VERSION ""

NS_ :

BS_:

BU_: XXX

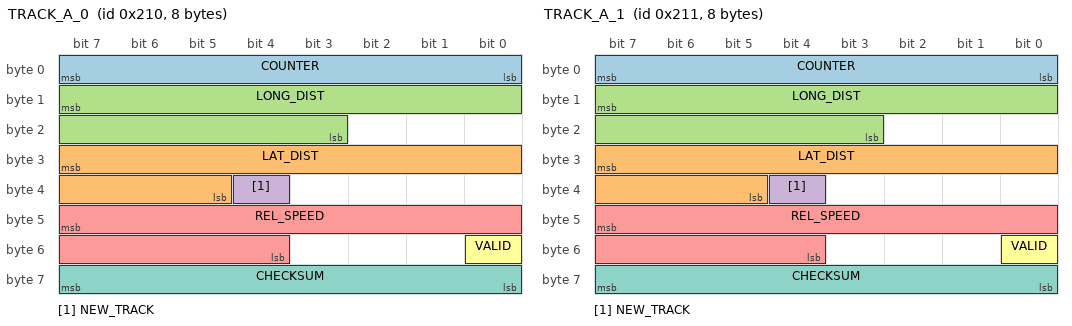
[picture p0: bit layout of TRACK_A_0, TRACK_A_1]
BO_ 528 TRACK_A_0: 8 XXX
 SG_ COUNTER : 7|8@0+ (1,0) [0|255] "" XXX
 SG_ LAT_DIST : 31|11@0- (0.04,0) [-50|50] "m" XXX
 SG_ LONG_DIST : 15|13@0+ (0.04,0) [0|300] "m" XXX
 SG_ NEW_TRACK : 36|1@0+ (1,0) [0|1] "" XXX
 SG_ REL_SPEED : 47|12@0- (0.025,0) [-100|100] "m/s" XXX
 SG_ VALID : 48|1@0+ (1,0) [0|1] "" XXX
 SG_ CHECKSUM : 63|8@0+ (1,0) [0|255] "" XXX

BO_ 529 TRACK_A_1: 8 XXX
 SG_ COUNTER : 7|8@0+ (1,0) [0|255] "" XXX
 SG_ LAT_DIST : 31|11@0- (0.04,0) [-50|50] "m" XXX
 SG_ LONG_DIST : 15|13@0+ (0.04,0) [0|300] "m" XXX
 SG_ NEW_TRACK : 36|1@0+ (1,0) [0|1] "" XXX
 SG_ REL_SPEED : 47|12@0- (0.025,0) [-100|100] "m/s" XXX
 SG_ VALID : 48|1@0+ (1,0) [0|1] "" XXX
 SG_ CHECKSUM : 63|8@0+ (1,0) [0|255] "" XXX

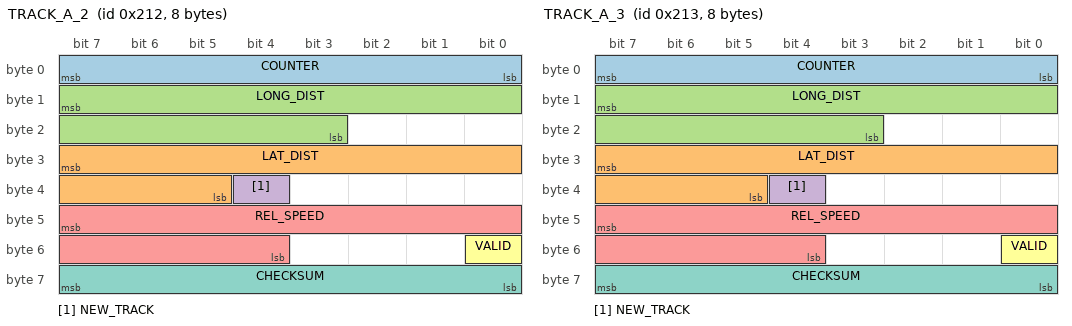
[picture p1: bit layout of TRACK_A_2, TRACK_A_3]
BO_ 530 TRACK_A_2: 8 XXX
 SG_ COUNTER : 7|8@0+ (1,0) [0|255] "" XXX
 SG_ LAT_DIST : 31|11@0- (0.04,0) [-50|50] "m" XXX
 SG_ LONG_DIST : 15|13@0+ (0.04,0) [0|300] "m" XXX
 SG_ NEW_TRACK : 36|1@0+ (1,0) [0|1] "" XXX
 SG_ REL_SPEED : 47|12@0- (0.025,0) [-100|100] "m/s" XXX
 SG_ VALID : 48|1@0+ (1,0) [0|1] "" XXX
 SG_ CHECKSUM : 63|8@0+ (1,0) [0|255] "" XXX

BO_ 531 TRACK_A_3: 8 XXX
 SG_ COUNTER : 7|8@0+ (1,0) [0|255] "" XXX
 SG_ LAT_DIST : 31|11@0- (0.04,0) [-50|50] "m" XXX
 SG_ LONG_DIST : 15|13@0+ (0.04,0) [0|300] "m" XXX
 SG_ NEW_TRACK : 36|1@0+ (1,0) [0|1] "" XXX
 SG_ REL_SPEED : 47|12@0- (0.025,0) [-100|100] "m/s" XXX
 SG_ VALID : 48|1@0+ (1,0) [0|1] "" XXX
 SG_ CHECKSUM : 63|8@0+ (1,0) [0|255] "" XXX

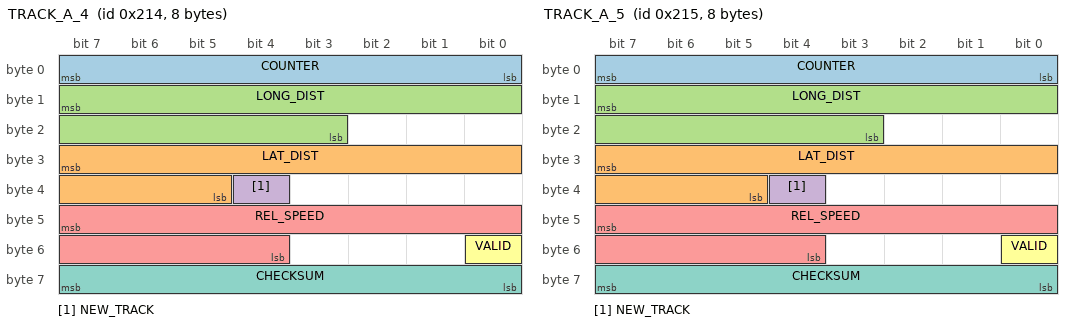
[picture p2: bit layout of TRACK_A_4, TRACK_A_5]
BO_ 532 TRACK_A_4: 8 XXX
 SG_ COUNTER : 7|8@0+ (1,0) [0|255] "" XXX
 SG_ LAT_DIST : 31|11@0- (0.04,0) [-50|50] "m" XXX
 SG_ LONG_DIST : 15|13@0+ (0.04,0) [0|300] "m" XXX
 SG_ NEW_TRACK : 36|1@0+ (1,0) [0|1] "" XXX
 SG_ REL_SPEED : 47|12@0- (0.025,0) [-100|100] "m/s" XXX
 SG_ VALID : 48|1@0+ (1,0) [0|1] "" XXX
 SG_ CHECKSUM : 63|8@0+ (1,0) [0|255] "" XXX

BO_ 533 TRACK_A_5: 8 XXX
 SG_ COUNTER : 7|8@0+ (1,0) [0|255] "" XXX
 SG_ LAT_DIST : 31|11@0- (0.04,0) [-50|50] "m" XXX
 SG_ LONG_DIST : 15|13@0+ (0.04,0) [0|300] "m" XXX
 SG_ NEW_TRACK : 36|1@0+ (1,0) [0|1] "" XXX
 SG_ REL_SPEED : 47|12@0- (0.025,0) [-100|100] "m/s" XXX
 SG_ VALID : 48|1@0+ (1,0) [0|1] "" XXX
 SG_ CHECKSUM : 63|8@0+ (1,0) [0|255] "" XXX

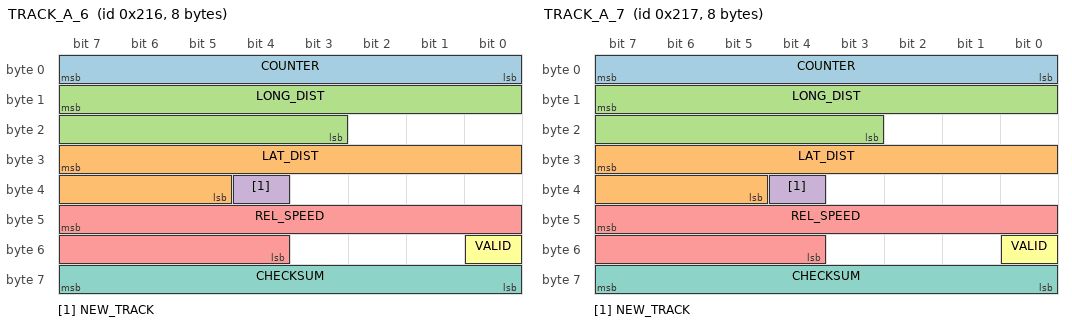
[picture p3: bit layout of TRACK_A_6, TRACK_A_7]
BO_ 534 TRACK_A_6: 8 XXX
 SG_ COUNTER : 7|8@0+ (1,0) [0|255] "" XXX
 SG_ LAT_DIST : 31|11@0- (0.04,0) [-50|50] "m" XXX
 SG_ LONG_DIST : 15|13@0+ (0.04,0) [0|300] "m" XXX
 SG_ NEW_TRACK : 36|1@0+ (1,0) [0|1] "" XXX
 SG_ REL_SPEED : 47|12@0- (0.025,0) [-100|100] "m/s" XXX
 SG_ VALID : 48|1@0+ (1,0) [0|1] "" XXX
 SG_ CHECKSUM : 63|8@0+ (1,0) [0|255] "" XXX

BO_ 535 TRACK_A_7: 8 XXX
 SG_ COUNTER : 7|8@0+ (1,0) [0|255] "" XXX
 SG_ LAT_DIST : 31|11@0- (0.04,0) [-50|50] "m" XXX
 SG_ LONG_DIST : 15|13@0+ (0.04,0) [0|300] "m" XXX
 SG_ NEW_TRACK : 36|1@0+ (1,0) [0|1] "" XXX
 SG_ REL_SPEED : 47|12@0- (0.025,0) [-100|100] "m/s" XXX
 SG_ VALID : 48|1@0+ (1,0) [0|1] "" XXX
 SG_ CHECKSUM : 63|8@0+ (1,0) [0|255] "" XXX

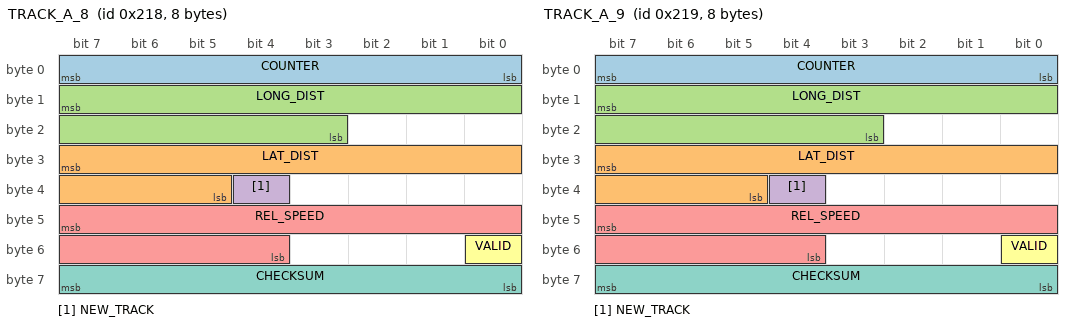
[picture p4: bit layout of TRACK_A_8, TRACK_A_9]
BO_ 536 TRACK_A_8: 8 XXX
 SG_ COUNTER : 7|8@0+ (1,0) [0|255] "" XXX
 SG_ LAT_DIST : 31|11@0- (0.04,0) [-50|50] "m" XXX
 SG_ LONG_DIST : 15|13@0+ (0.04,0) [0|300] "m" XXX
 SG_ NEW_TRACK : 36|1@0+ (1,0) [0|1] "" XXX
 SG_ REL_SPEED : 47|12@0- (0.025,0) [-100|100] "m/s" XXX
 SG_ VALID : 48|1@0+ (1,0) [0|1] "" XXX
 SG_ CHECKSUM : 63|8@0+ (1,0) [0|255] "" XXX

BO_ 537 TRACK_A_9: 8 XXX
 SG_ COUNTER : 7|8@0+ (1,0) [0|255] "" XXX
 SG_ LAT_DIST : 31|11@0- (0.04,0) [-50|50] "m" XXX
 SG_ LONG_DIST : 15|13@0+ (0.04,0) [0|300] "m" XXX
 SG_ NEW_TRACK : 36|1@0+ (1,0) [0|1] "" XXX
 SG_ REL_SPEED : 47|12@0- (0.025,0) [-100|100] "m/s" XXX
 SG_ VALID : 48|1@0+ (1,0) [0|1] "" XXX
 SG_ CHECKSUM : 63|8@0+ (1,0) [0|255] "" XXX

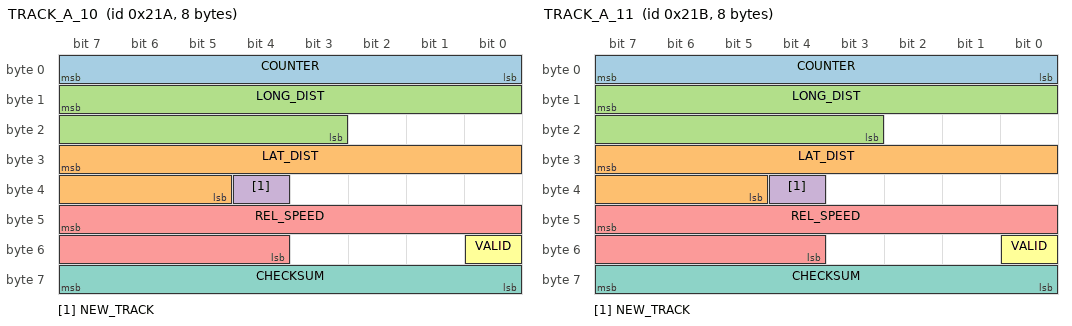
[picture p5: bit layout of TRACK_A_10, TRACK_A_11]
BO_ 538 TRACK_A_10: 8 XXX
 SG_ COUNTER : 7|8@0+ (1,0) [0|255] "" XXX
 SG_ LAT_DIST : 31|11@0- (0.04,0) [-50|50] "m" XXX
 SG_ LONG_DIST : 15|13@0+ (0.04,0) [0|300] "m" XXX
 SG_ NEW_TRACK : 36|1@0+ (1,0) [0|1] "" XXX
 SG_ REL_SPEED : 47|12@0- (0.025,0) [-100|100] "m/s" XXX
 SG_ VALID : 48|1@0+ (1,0) [0|1] "" XXX
 SG_ CHECKSUM : 63|8@0+ (1,0) [0|255] "" XXX

BO_ 539 TRACK_A_11: 8 XXX
 SG_ COUNTER : 7|8@0+ (1,0) [0|255] "" XXX
 SG_ LAT_DIST : 31|11@0- (0.04,0) [-50|50] "m" XXX
 SG_ LONG_DIST : 15|13@0+ (0.04,0) [0|300] "m" XXX
 SG_ NEW_TRACK : 36|1@0+ (1,0) [0|1] "" XXX
 SG_ REL_SPEED : 47|12@0- (0.025,0) [-100|100] "m/s" XXX
 SG_ VALID : 48|1@0+ (1,0) [0|1] "" XXX
 SG_ CHECKSUM : 63|8@0+ (1,0) [0|255] "" XXX

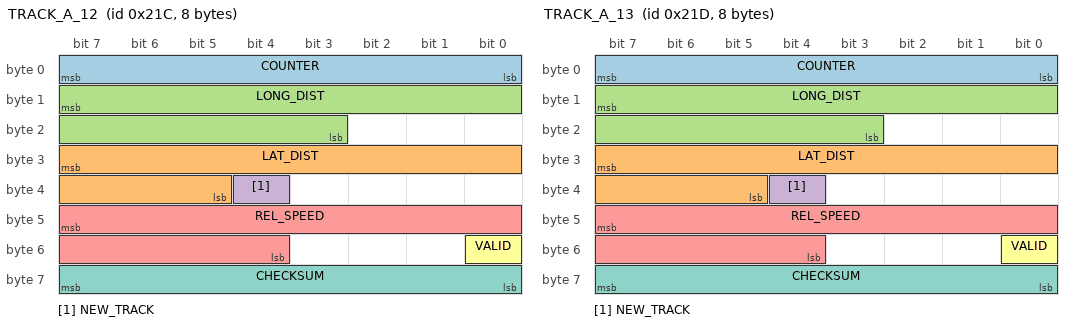
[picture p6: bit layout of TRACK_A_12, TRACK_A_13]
BO_ 540 TRACK_A_12: 8 XXX
 SG_ COUNTER : 7|8@0+ (1,0) [0|255] "" XXX
 SG_ LAT_DIST : 31|11@0- (0.04,0) [-50|50] "m" XXX
 SG_ LONG_DIST : 15|13@0+ (0.04,0) [0|300] "m" XXX
 SG_ NEW_TRACK : 36|1@0+ (1,0) [0|1] "" XXX
 SG_ REL_SPEED : 47|12@0- (0.025,0) [-100|100] "m/s" XXX
 SG_ VALID : 48|1@0+ (1,0) [0|1] "" XXX
 SG_ CHECKSUM : 63|8@0+ (1,0) [0|255] "" XXX

BO_ 541 TRACK_A_13: 8 XXX
 SG_ COUNTER : 7|8@0+ (1,0) [0|255] "" XXX
 SG_ LAT_DIST : 31|11@0- (0.04,0) [-50|50] "m" XXX
 SG_ LONG_DIST : 15|13@0+ (0.04,0) [0|300] "m" XXX
 SG_ NEW_TRACK : 36|1@0+ (1,0) [0|1] "" XXX
 SG_ REL_SPEED : 47|12@0- (0.025,0) [-100|100] "m/s" XXX
 SG_ VALID : 48|1@0+ (1,0) [0|1] "" XXX
 SG_ CHECKSUM : 63|8@0+ (1,0) [0|255] "" XXX

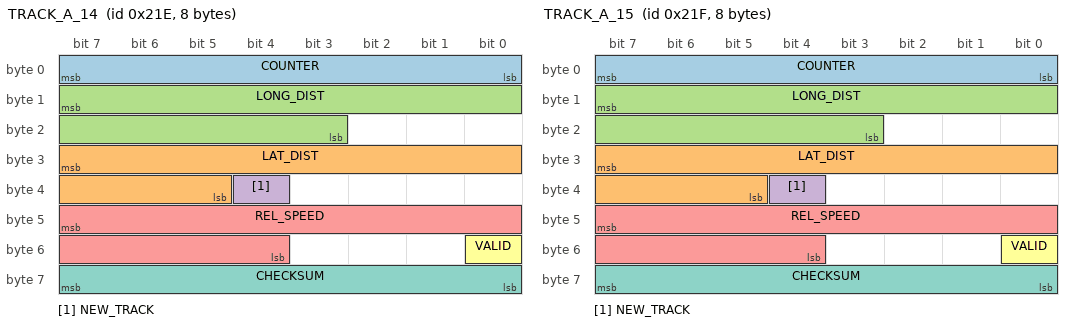
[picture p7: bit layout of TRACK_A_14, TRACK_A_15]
BO_ 542 TRACK_A_14: 8 XXX
 SG_ COUNTER : 7|8@0+ (1,0) [0|255] "" XXX
 SG_ LAT_DIST : 31|11@0- (0.04,0) [-50|50] "m" XXX
 SG_ LONG_DIST : 15|13@0+ (0.04,0) [0|300] "m" XXX
 SG_ NEW_TRACK : 36|1@0+ (1,0) [0|1] "" XXX
 SG_ REL_SPEED : 47|12@0- (0.025,0) [-100|100] "m/s" XXX
 SG_ VALID : 48|1@0+ (1,0) [0|1] "" XXX
 SG_ CHECKSUM : 63|8@0+ (1,0) [0|255] "" XXX

BO_ 543 TRACK_A_15: 8 XXX
 SG_ COUNTER : 7|8@0+ (1,0) [0|255] "" XXX
 SG_ LAT_DIST : 31|11@0- (0.04,0) [-50|50] "m" XXX
 SG_ LONG_DIST : 15|13@0+ (0.04,0) [0|300] "m" XXX
 SG_ NEW_TRACK : 36|1@0+ (1,0) [0|1] "" XXX
 SG_ REL_SPEED : 47|12@0- (0.025,0) [-100|100] "m/s" XXX
 SG_ VALID : 48|1@0+ (1,0) [0|1] "" XXX
 SG_ CHECKSUM : 63|8@0+ (1,0) [0|255] "" XXX

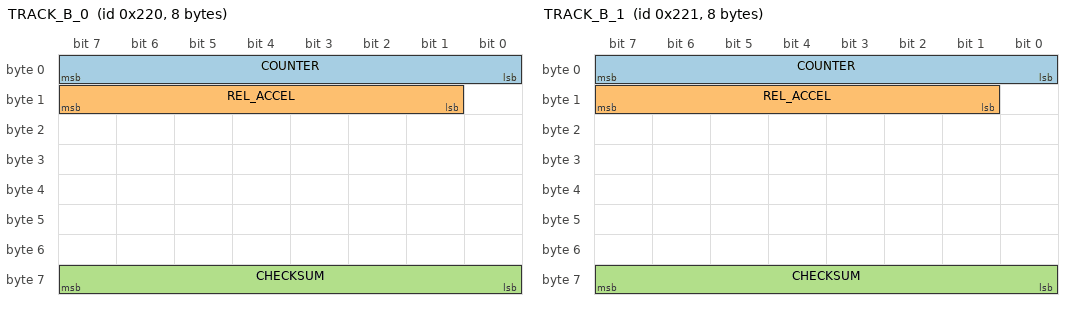
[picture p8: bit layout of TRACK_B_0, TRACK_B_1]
BO_ 544 TRACK_B_0: 8 XXX
 SG_ COUNTER : 7|8@0+ (1,0) [0|255] "" XXX
 SG_ REL_ACCEL : 15|7@0- (1,0) [-64|63] "" XXX
 SG_ CHECKSUM : 63|8@0+ (1,0) [0|255] "" XXX

BO_ 545 TRACK_B_1: 8 XXX
 SG_ COUNTER : 7|8@0+ (1,0) [0|255] "" XXX
 SG_ REL_ACCEL : 15|7@0- (1,0) [-64|63] "" XXX
 SG_ CHECKSUM : 63|8@0+ (1,0) [0|255] "" XXX

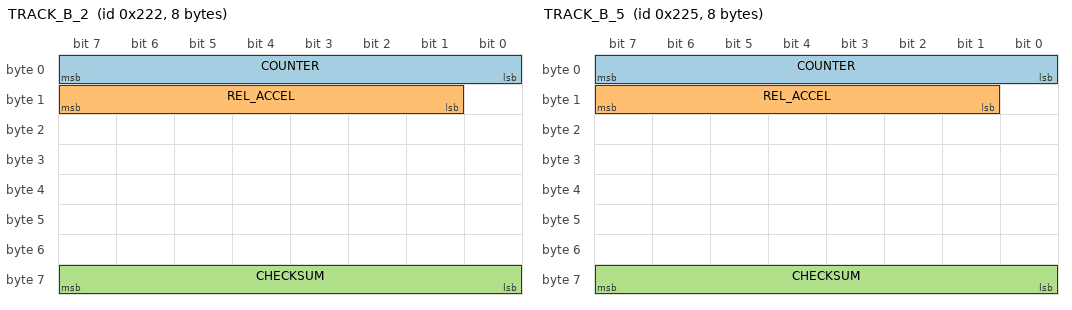
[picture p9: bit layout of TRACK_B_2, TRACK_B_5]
BO_ 546 TRACK_B_2: 8 XXX
 SG_ COUNTER : 7|8@0+ (1,0) [0|255] "" XXX
 SG_ REL_ACCEL : 15|7@0- (1,0) [-64|63] "" XXX
 SG_ CHECKSUM : 63|8@0+ (1,0) [0|255] "" XXX

BO_ 547 undefined: 8 XXX

BO_ 548 BRAKING_PEDAL: 8 XXX
 SG_ IS_BRAKING : 5|1@0+ (1,0) [0|3] "" XXX

BO_ 549 TRACK_B_5: 8 XXX
 SG_ COUNTER : 7|8@0+ (1,0) [0|255] "" XXX
 SG_ REL_ACCEL : 15|7@0- (1,0) [-64|63] "" XXX
 SG_ CHECKSUM : 63|8@0+ (1,0) [0|255] "" XXX

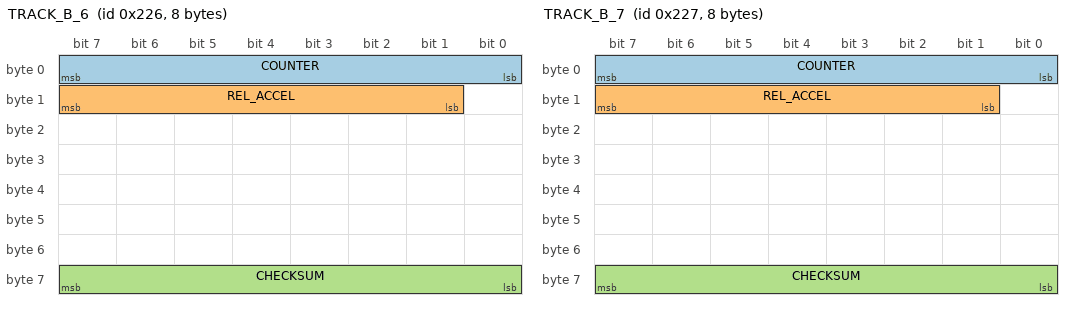
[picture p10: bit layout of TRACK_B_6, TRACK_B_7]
BO_ 550 TRACK_B_6: 8 XXX
 SG_ COUNTER : 7|8@0+ (1,0) [0|255] "" XXX
 SG_ REL_ACCEL : 15|7@0- (1,0) [-64|63] "" XXX
 SG_ CHECKSUM : 63|8@0+ (1,0) [0|255] "" XXX

BO_ 551 TRACK_B_7: 8 XXX
 SG_ COUNTER : 7|8@0+ (1,0) [0|255] "" XXX
 SG_ REL_ACCEL : 15|7@0- (1,0) [-64|63] "" XXX
 SG_ CHECKSUM : 63|8@0+ (1,0) [0|255] "" XXX

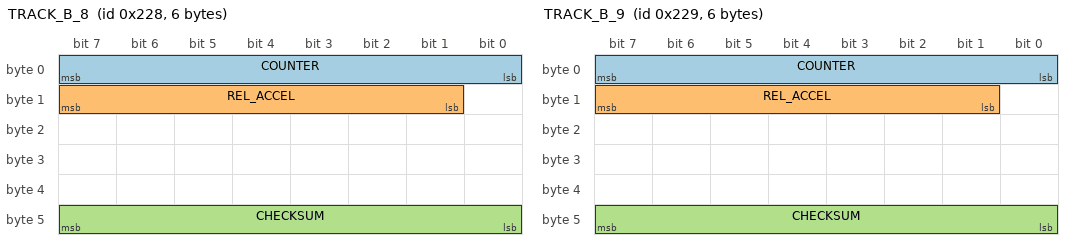
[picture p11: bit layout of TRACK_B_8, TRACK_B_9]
BO_ 552 TRACK_B_8: 6 XXX
 SG_ COUNTER : 7|8@0+ (1,0) [0|255] "" XXX
 SG_ REL_ACCEL : 15|7@0- (1,0) [-64|63] "" XXX
 SG_ CHECKSUM : 47|8@0+ (1,0) [0|255] "" XXX

BO_ 553 TRACK_B_9: 6 XXX
 SG_ COUNTER : 7|8@0+ (1,0) [0|255] "" XXX
 SG_ REL_ACCEL : 15|7@0- (1,0) [-64|63] "" XXX
 SG_ CHECKSUM : 47|8@0+ (1,0) [0|255] "" XXX

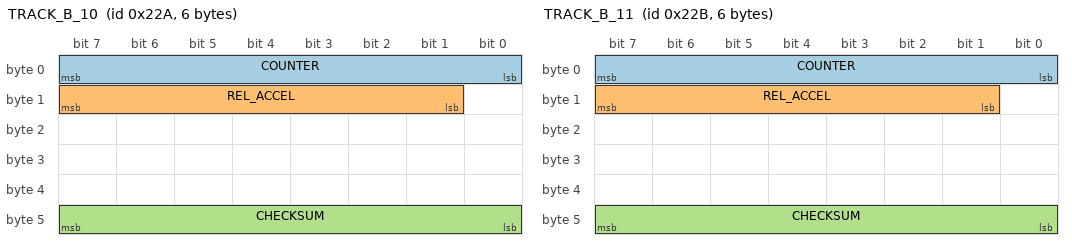
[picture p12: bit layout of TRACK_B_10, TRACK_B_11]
BO_ 554 TRACK_B_10: 6 XXX
 SG_ COUNTER : 7|8@0+ (1,0) [0|255] "" XXX
 SG_ REL_ACCEL : 15|7@0- (1,0) [-64|63] "" XXX
 SG_ CHECKSUM : 47|8@0+ (1,0) [0|255] "" XXX

BO_ 555 TRACK_B_11: 6 XXX
 SG_ COUNTER : 7|8@0+ (1,0) [0|255] "" XXX
 SG_ REL_ACCEL : 15|7@0- (1,0) [-64|63] "" XXX
 SG_ CHECKSUM : 47|8@0+ (1,0) [0|255] "" XXX

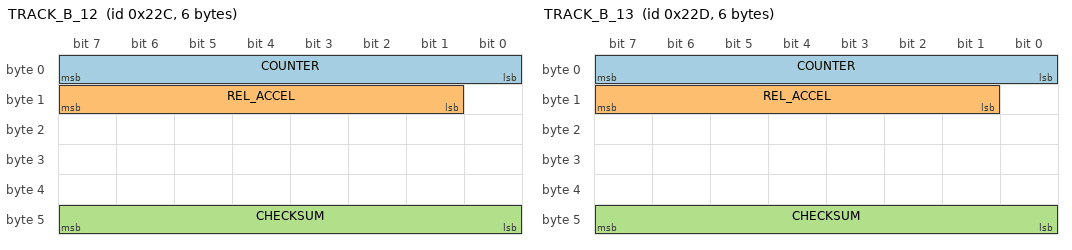
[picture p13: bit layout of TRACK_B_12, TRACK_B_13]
BO_ 556 TRACK_B_12: 6 XXX
 SG_ COUNTER : 7|8@0+ (1,0) [0|255] "" XXX
 SG_ REL_ACCEL : 15|7@0- (1,0) [-64|63] "" XXX
 SG_ CHECKSUM : 47|8@0+ (1,0) [0|255] "" XXX

BO_ 557 TRACK_B_13: 6 XXX
 SG_ COUNTER : 7|8@0+ (1,0) [0|255] "" XXX
 SG_ REL_ACCEL : 15|7@0- (1,0) [-64|63] "" XXX
 SG_ CHECKSUM : 47|8@0+ (1,0) [0|255] "" XXX

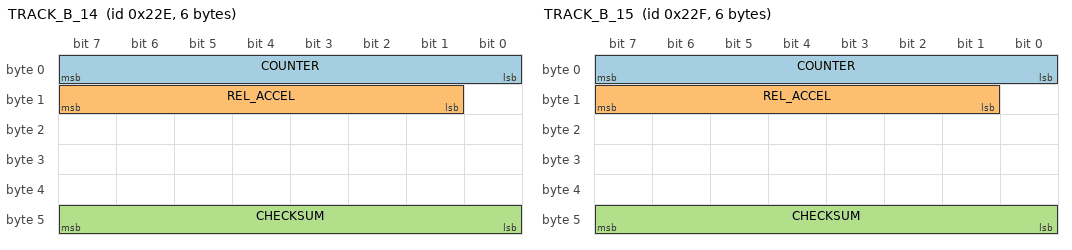
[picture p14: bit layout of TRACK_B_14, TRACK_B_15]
BO_ 558 TRACK_B_14: 6 XXX
 SG_ COUNTER : 7|8@0+ (1,0) [0|255] "" XXX
 SG_ REL_ACCEL : 15|7@0- (1,0) [-64|63] "" XXX
 SG_ CHECKSUM : 47|8@0+ (1,0) [0|255] "" XXX

BO_ 559 TRACK_B_15: 6 XXX
 SG_ COUNTER : 7|8@0+ (1,0) [0|255] "" XXX
 SG_ REL_ACCEL : 15|7@0- (1,0) [-64|63] "" XXX
 SG_ CHECKSUM : 47|8@0+ (1,0) [0|255] "" XXX

BO_ 1552 CONTAINS_LRES_SPEED: 8 XXX
 SG_ SPEED_LOWRES : 16|8@1+ (1,0) [0|255] "km/h?" XXX
 SG_ NEW_SIGNAL_1 : 7|8@0+ (1,0) [0|255] "" XXX

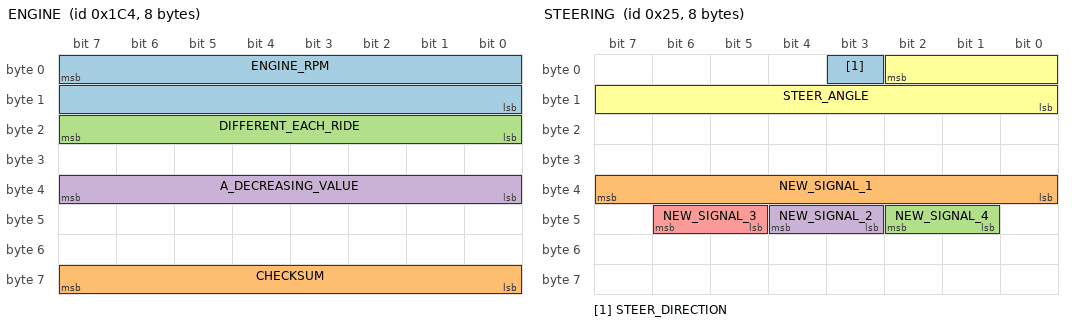
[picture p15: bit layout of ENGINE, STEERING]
BO_ 452 ENGINE: 8 XXX
 SG_ ENGINE_RPM : 7|16@0+ (1,0) [0|65535] "rpm" XXX
 SG_ CHECKSUM : 63|8@0+ (1,0) [0|255] "" XXX
 SG_ DIFFERENT_EACH_RIDE : 23|8@0+ (1,0) [0|255] "" XXX
 SG_ A_DECREASING_VALUE : 39|8@0+ (1,0) [0|255] "" XXX

BO_ 37 STEERING: 8 XXX
 SG_ STEER_DIRECTION : 3|1@0+ (1,0) [0|1] "" XXX
 SG_ NEW_SIGNAL_1 : 39|8@0+ (1,0) [0|255] "" XXX
 SG_ NEW_SIGNAL_4 : 42|2@0- (1,0) [0|3] "" XXX
 SG_ NEW_SIGNAL_2 : 44|2@0- (1,0) [0|255] "" XXX
 SG_ NEW_SIGNAL_3 : 46|2@0- (1,0) [0|3] "" XXX
 SG_ STEER_ANGLE : 2|11@0- (1,0) [-350|350] "" XXX

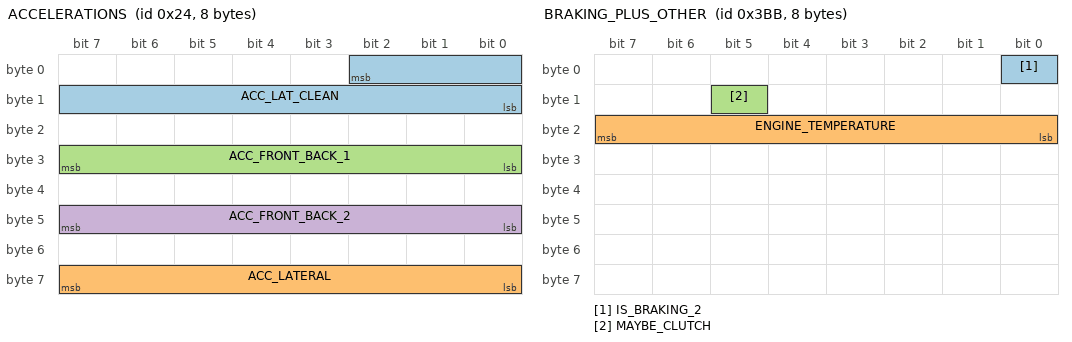
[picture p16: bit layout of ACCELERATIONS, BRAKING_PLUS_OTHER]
BO_ 36 ACCELERATIONS: 8 XXX
 SG_ ACC_LAT_CLEAN : 2|11@0- (1,0) [0|255] "" XXX
 SG_ ACC_LATERAL : 63|8@0- (1,0) [0|255] "" XXX
 SG_ ACC_FRONT_BACK_1 : 31|8@0- (1,0) [0|255] "" XXX
 SG_ ACC_FRONT_BACK_2 : 47|8@0- (1,0) [0|255] "" XXX

BO_ 947 LOW_RES_INDICATORS: 8 XXX
 SG_ LOW_RES_ACC_PEDAL : 23|7@0+ (1,0) [0|63] "" XXX
 SG_ LOW_RES_RPM : 7|16@0+ (1,0) [0|255] "rpm" XXX

BO_ 955 BRAKING_PLUS_OTHER: 8 XXX
 SG_ IS_BRAKING_2 : 0|1@0+ (1,0) [0|1] "" XXX
 SG_ ENGINE_TEMPERATURE : 23|8@0+ (1,0) [0|255] "" XXX
 SG_ MAYBE_CLUTCH : 13|1@0+ (1,0) [0|1] "" XXX

BO_ 1595 CONTAINS_TIME: 8 XXX
 SG_ TIME_ON : 55|16@0+ (0.1,0) [0|65535] "s" XXX
 SG_ BETWEEN_RIDES : 7|32@0+ (1,0) [0|4294967295] "" XXX

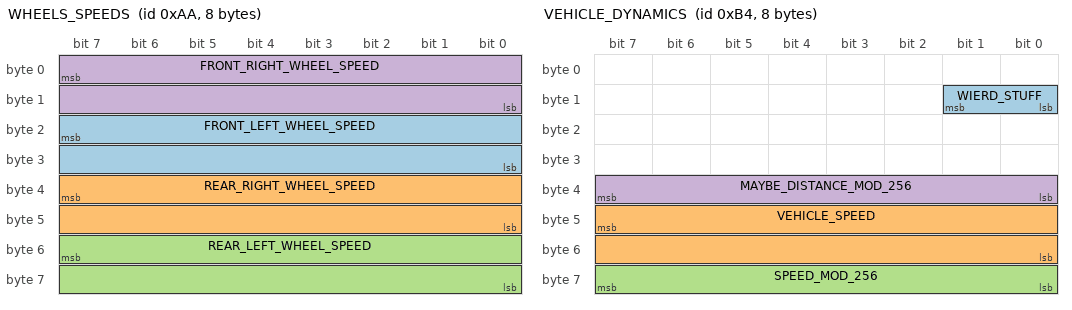
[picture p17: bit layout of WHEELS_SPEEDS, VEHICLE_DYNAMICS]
BO_ 170 WHEELS_SPEEDS: 8 XXX
 SG_ FRONT_LEFT_WHEEL_SPEED : 23|16@0+ (0.01,-67.67) [0|65535] "km/h" XXX
 SG_ REAR_RIGHT_WHEEL_SPEED : 39|16@0+ (0.01,-67.67) [0|65535] "km/h" XXX
 SG_ REAR_LEFT_WHEEL_SPEED : 55|16@0+ (0.01,-67.67) [0|65535] "km/h" XXX
 SG_ FRONT_RIGHT_WHEEL_SPEED : 7|16@0+ (0.01,-67.67) [0|65535] "km/h" XXX

BO_ 180 VEHICLE_DYNAMICS: 8 XXX
 SG_ WIERD_STUFF : 8|2@1+ (1,0) [0|3] "" XXX
 SG_ VEHICLE_SPEED : 47|16@0+ (0.01,0) [0|255] "km/h" XXX
 SG_ SPEED_MOD_256 : 63|8@0- (1,0) [0|255] "" XXX
 SG_ MAYBE_DISTANCE_MOD_256 : 39|8@0+ (1,0) [0|255] "" XXX

BO_ 186 NEW_MSG_9: 8 XXX
 SG_ NEW_SIGNAL_2 : 31|8@0+ (1,0) [0|255] "" XXX

BO_ 565 NEW_MSG_10: 8 XXX

BO_ 464 NEW_MSG_11: 8 XXX

BO_ 426 NEW_MSG_5: 8 XXX
 SG_ CONSTANT : 47|8@0+ (1,0) [0|255] "" XXX

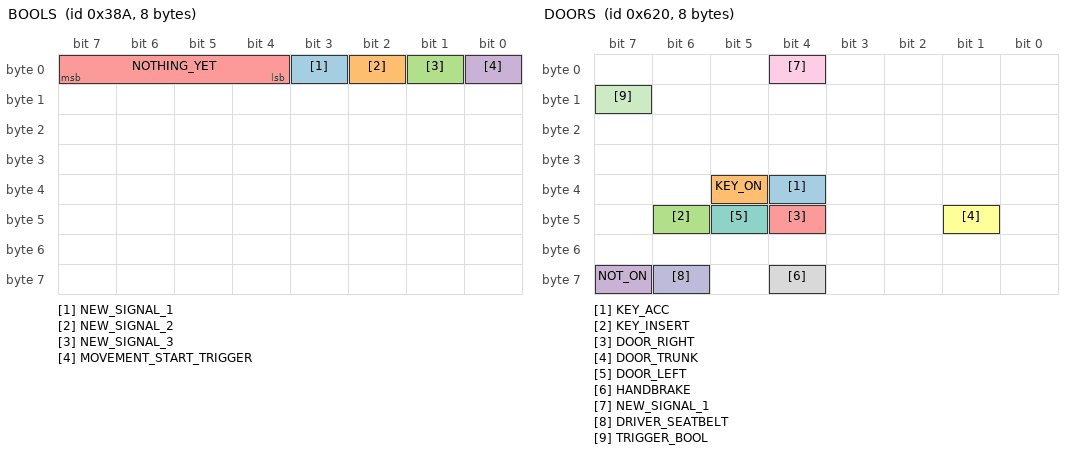
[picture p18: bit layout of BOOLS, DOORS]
BO_ 906 BOOLS: 8 XXX
 SG_ NEW_SIGNAL_1 : 3|1@0+ (1,0) [0|1] "" XXX
 SG_ NEW_SIGNAL_2 : 2|1@0+ (1,0) [0|1] "" XXX
 SG_ NEW_SIGNAL_3 : 1|1@0+ (1,0) [0|1] "" XXX
 SG_ MOVEMENT_START_TRIGGER : 0|1@0+ (1,0) [0|1] "" XXX
 SG_ NOTHING_YET : 7|4@0+ (1,0) [0|127] "" XXX

BO_ 979 LOW_RES_ACCELERATOR: 8 XXX
 SG_ VERY_LRES_ACC : 7|16@0+ (1,0) [0|65535] "" XXX

BO_ 1600 SLOW_VARIABLE_INFOS: 8 XXX
 SG_ CHANGES_EACH_RIDE : 31|8@0+ (1,0) [0|255] "" XXX
 SG_ INCREASING_VALUE_FUEL : 47|8@0+ (1,0) [0|255] "" XXX

BO_ 1568 DOORS: 8 XXX
 SG_ KEY_ACC : 36|1@0+ (1,0) [0|1] "" XXX
 SG_ KEY_ON : 37|1@0+ (1,0) [0|1] "" XXX
 SG_ KEY_INSERT : 46|1@0+ (1,0) [0|1] "" XXX
 SG_ NOT_ON : 63|1@0+ (1,0) [0|1] "" XXX
 SG_ DOOR_RIGHT : 44|1@0+ (1,0) [0|3] "" XXX
 SG_ DOOR_TRUNK : 41|1@1+ (1,0) [0|3] "" XXX
 SG_ DOOR_LEFT : 45|1@0+ (1,0) [0|255] "" XXX
 SG_ HANDBRAKE : 60|1@0+ (1,0) [0|3] "" XXX
 SG_ NEW_SIGNAL_1 : 4|1@0+ (1,0) [0|1] "" XXX
 SG_ DRIVER_SEATBELT : 62|1@0+ (1,0) [0|1] "" XXX
 SG_ TRIGGER_BOOL : 15|1@0+ (1,0) [0|1] "" XXX

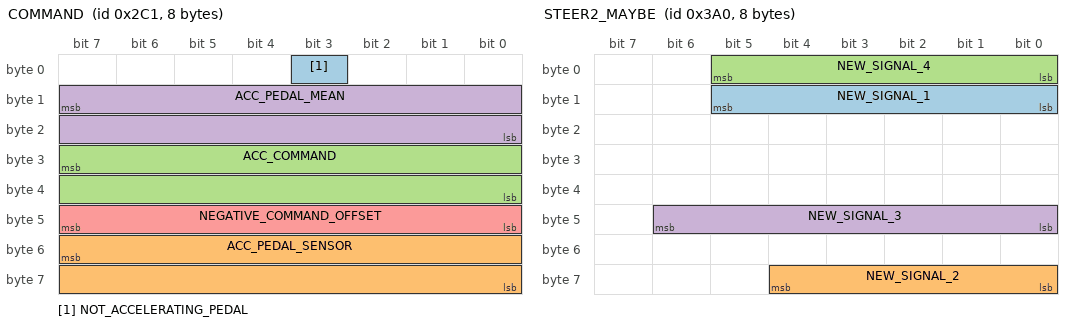
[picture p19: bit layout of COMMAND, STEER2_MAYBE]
BO_ 705 COMMAND: 8 XXX
 SG_ NOT_ACCELERATING_PEDAL : 3|1@1+ (1,0) [0|1] "" XXX
 SG_ ACC_PEDAL_SENSOR : 55|16@0+ (1,0) [0|65535] "" XXX
 SG_ ACC_COMMAND : 31|16@0- (1,0) [0|7] "" XXX
 SG_ ACC_PEDAL_MEAN : 15|16@0- (1,0) [0|255] "" XXX
 SG_ NEGATIVE_COMMAND_OFFSET : 47|8@0- (1,0) [0|255] "" XXX

BO_ 928 STEER2_MAYBE: 8 XXX
 SG_ NEW_SIGNAL_1 : 13|6@0+ (1,0) [0|63] "" XXX
 SG_ NEW_SIGNAL_2 : 60|5@0+ (1,0) [0|31] "" XXX
 SG_ NEW_SIGNAL_4 : 5|6@0+ (1,0) [0|255] "" XXX
 SG_ NEW_SIGNAL_3 : 46|7@0+ (1,0) [0|15] "" XXX

BO_ 896 LONG_TERM_2: 8 XXX
 SG_ NEW_SIGNAL_1 : 55|8@0+ (1,0) [0|255] "" XXX

BO_ 944 LONG_TERM_MSG: 8 XXX
 SG_ LONG_TERM_SIGN : 31|8@0+ (1,0) [0|255] "" XXX

BO_ 1553 TOTAL_DIST: 8 XXX
 SG_ TOTAL_DISTANCE : 55|16@0+ (1,0) [0|65535] "" XXX

BO_ 1572 WHY_THESE_VALUES: 8 XXX

BO_ 1555 BETWEEN_RIDES_CHANGE_1: 8 XXX
 SG_ BETWEEN_RIDES : 23|1@0+ (1,0) [0|1] "" XXX

BO_ 1090 ASYNC_MSG_ACK: 8 XXX
 SG_ NEW_SIGNAL_1 : 13|2@0+ (1,0) [0|1] "" XXX
 SG_ NEW_SIGNAL_2 : 23|1@0+ (1,0) [0|1] "" XXX

BO_ 1592 NEW_MSG_14: 8 XXX
 SG_ DOORS_LOCKED2 : 20|1@0+ (1,0) [0|1] "" XXX
 SG_ DOORS_LOCKED1 : 16|1@0+ (1,0) [0|1] "" XXX

BO_ 1017 undefined: 8 XXX

BO_ 608 NEW_MSG_6: 8 XXX
 SG_ VERY_SMALL_SIGNAL2 : 56|1@0+ (1,0) [0|255] "" XXX
 SG_ VERY_SMALL_SIGNAL1 : 0|1@0+ (1,0) [0|1] "" XXX

BO_ 1088 NEW_MSG_2: 8 XXX

BO_ 945 BETWEEN_RIDES_CHANGES_2: 8 XXX
 SG_ BETWEEN_RIDES : 24|1@0+ (1,0) [0|65535] "" XXX

CM_ SG_ 1552 SPEED_LOWRES "Negative values to check";
CM_ SG_ 452 CHECKSUM "Follows path of RPMs but more precise & 1 byte only";
CM_ SG_ 452 A_DECREASING_VALUE "stabilizes to 62 after ~10 mins";
CM_ SG_ 37 STEER_DIRECTION "Could be intended as 12 bit steering angle";
CM_ SG_ 37 STEER_ANGLE "can convert to degrees (imprecise) or percentage of max amplitude";
CM_ SG_ 36 ACC_FRONT_BACK_1 "more likely up-down";
CM_ SG_ 36 ACC_FRONT_BACK_2 "more likely front-back";
CM_ SG_ 947 LOW_RES_ACC_PEDAL "Follows rather closely other acceleration commands";
CM_ SG_ 947 LOW_RES_RPM "Mabe used for onboard display?";
CM_ SG_ 955 MAYBE_CLUTCH "might be related to shifting gears";
CM_ SG_ 1595 TIME_ON "Time since last ignition, tenth of seconds";
CM_ SG_ 1595 BETWEEN_RIDES "the fourth byte (at least) changes between rides";
CM_ SG_ 180 WIERD_STUFF "Might be a signed value on the whole two bytes (sometimes all set)";
CM_ SG_ 180 VEHICLE_SPEED "Roughly 2 seconds before wheel speeds";
CM_ SG_ 180 SPEED_MOD_256 "One byte speed, a bit before vehicle speed";
CM_ SG_ 180 MAYBE_DISTANCE_MOD_256 "Looks like measure for distance or wheel angle";
CM_ SG_ 906 MOVEMENT_START_TRIGGER "trigger of when speed becomes != 0";
CM_ SG_ 979 VERY_LRES_ACC "Power used by engine? moves alongside speed, very low res, goes from 0 to 9 max?";
CM_ SG_ 1600 CHANGES_EACH_RIDE "Small decrementation during some rides, possibly long term fuel";
CM_ SG_ 1600 INCREASING_VALUE_FUEL "Fuel/distance? Average fuel consumption?";
CM_ SG_ 705 NOT_ACCELERATING_PEDAL "Looks like opposite of accelerating bit";
CM_ SG_ 705 ACC_PEDAL_SENSOR "similar to pedal sensor maybe checksum.";
CM_ SG_ 705 ACC_COMMAND "Similar to other pedal indicator., cleaner, must be sent back to engine";
CM_ SG_ 705 ACC_PEDAL_MEAN "Actual sensor for pedal (works when engine off)";
CM_ SG_ 705 NEGATIVE_COMMAND_OFFSET "Mysterious for now";
CM_ SG_ 928 NEW_SIGNAL_1 "Very slow changing noisy value, 45-49 in 10 min";
CM_ SG_ 928 NEW_SIGNAL_2 "Other very slow changing 24-26 in 10 min";
CM_ SG_ 928 NEW_SIGNAL_4 "Inconsistent across rides";
CM_ SG_ 896 NEW_SIGNAL_1 "there is a difference at the beginning of 2017-10-31--12-04-05";
CM_ SG_ 1553 TOTAL_DISTANCE "Probably also contains the previous/two previous bytes but can't confirm";
CM_ SG_ 945 BETWEEN_RIDES "Might be others in the same message. at least this one";

CM_ "CHFFR_METRIC 37 STEER_ANGLE STEER_ANGLE 0.36 180; CHFFR_METRIC 452 ENGINE_RPM ENGINE_RPM 1 0; CHFFR_METRIC 955 ENGINE_TEMPERATURE ENGINE_TEMPERATURE 1 0";
